AUTOSAR XML (schema 00050)
package /MICROSAR/IoHwAb_swc/ComponentTypes
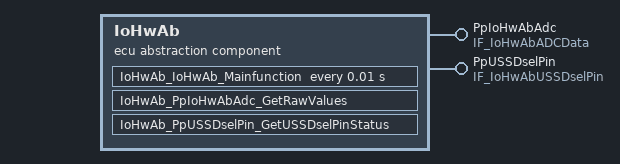
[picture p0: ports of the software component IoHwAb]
  ecu abstraction sw component type IoHwAb
    provide port PpIoHwAbAdc: provided-interface=IF_IoHwAbADCData
    provide port PpUSSDselPin: provided-interface=IF_IoHwAbUSSDselPin
    behavior IoHwAbInternalBehavior: handle-termination-and-restart=NO-SUPPORT
      operation invoked event OpEventIoHwAb_PpIoHwAbAdc_GetRawValues_GetRawValues_PpIoHwAbAdc: start-on-event=IoHwAb_PpIoHwAbAdc_GetRawValues, operation=PpIoHwAbAdc.GetRawValues
      timing event Timer_IoHwAb_IoHwAb_Mainfunction: start-on-event=IoHwAb_IoHwAb_Mainfunction, period=0.01
      operation invoked event OpEventIoHwAb_PpUSSDselPin_GetUSSDselPinStatus_GetUSSDselPinStatus_PpUSSDselPin: start-on-event=IoHwAb_PpUSSDselPin_GetUSSDselPinStatus, operation=PpUSSDselPin.GetUSSDselPinStatus
      port-api-options:
        enable-take-address=true, indirect-api=false, port=PpIoHwAbAdc
        enable-take-address=true, indirect-api=false, port=PpUSSDselPin
      runnable IoHwAb_PpIoHwAbAdc_GetRawValues: can-be-invoked-concurrently=true  # Runnable Entity for calling the Operation 'GetRawValues' of the Client/Server Port Prototype 'PpIoHwAbAdc'.
      runnable IoHwAb_IoHwAb_Mainfunction: can-be-invoked-concurrently=true
      runnable IoHwAb_PpUSSDselPin_GetUSSDselPinStatus: can-be-invoked-concurrently=true  # Runnable Entity for calling the Operation 'GetUSSDselPinStatus' of the Client/Server Port Prototype 'PpUSSDselPin'.
  swc implementation IoHwAbImplementation: programming-language=C, behavior=IoHwAbInternalBehavior
package /MICROSAR/IoHwAb_swc/DataTypes
  impl type IOHWAB_UINT16: range raw 0..65535, implementation-data-type=uint16
  impl type IOHWAB_UINT8: range raw 0..255, implementation-data-type=uint8
  impl type IOHWAB_BOOL: implementation-data-type=boolean
package /MICROSAR/IoHwAb_swc/Interfaces
  client server interface IF_IoHwAbADCData
    operation GetRawValues: possible-error=IF_IoHwAbADCData/IoHwAbApplicationError
      arg Channelndex: type=IOHWAB_UINT8, direction=IN
      arg ChannelRawValue: type=IOHWAB_UINT16, direction=OUT
    error IoHwAbApplicationError: error-code=1
  client server interface IF_IoHwAbUSSDselPin
    operation GetUSSDselPinStatus: possible-error=IF_IoHwAbUSSDselPin/IoHwAbApplicationError
      arg USSDselPinStatus: type=IOHWAB_BOOL, direction=IN
    error IoHwAbApplicationError: error-code=1
